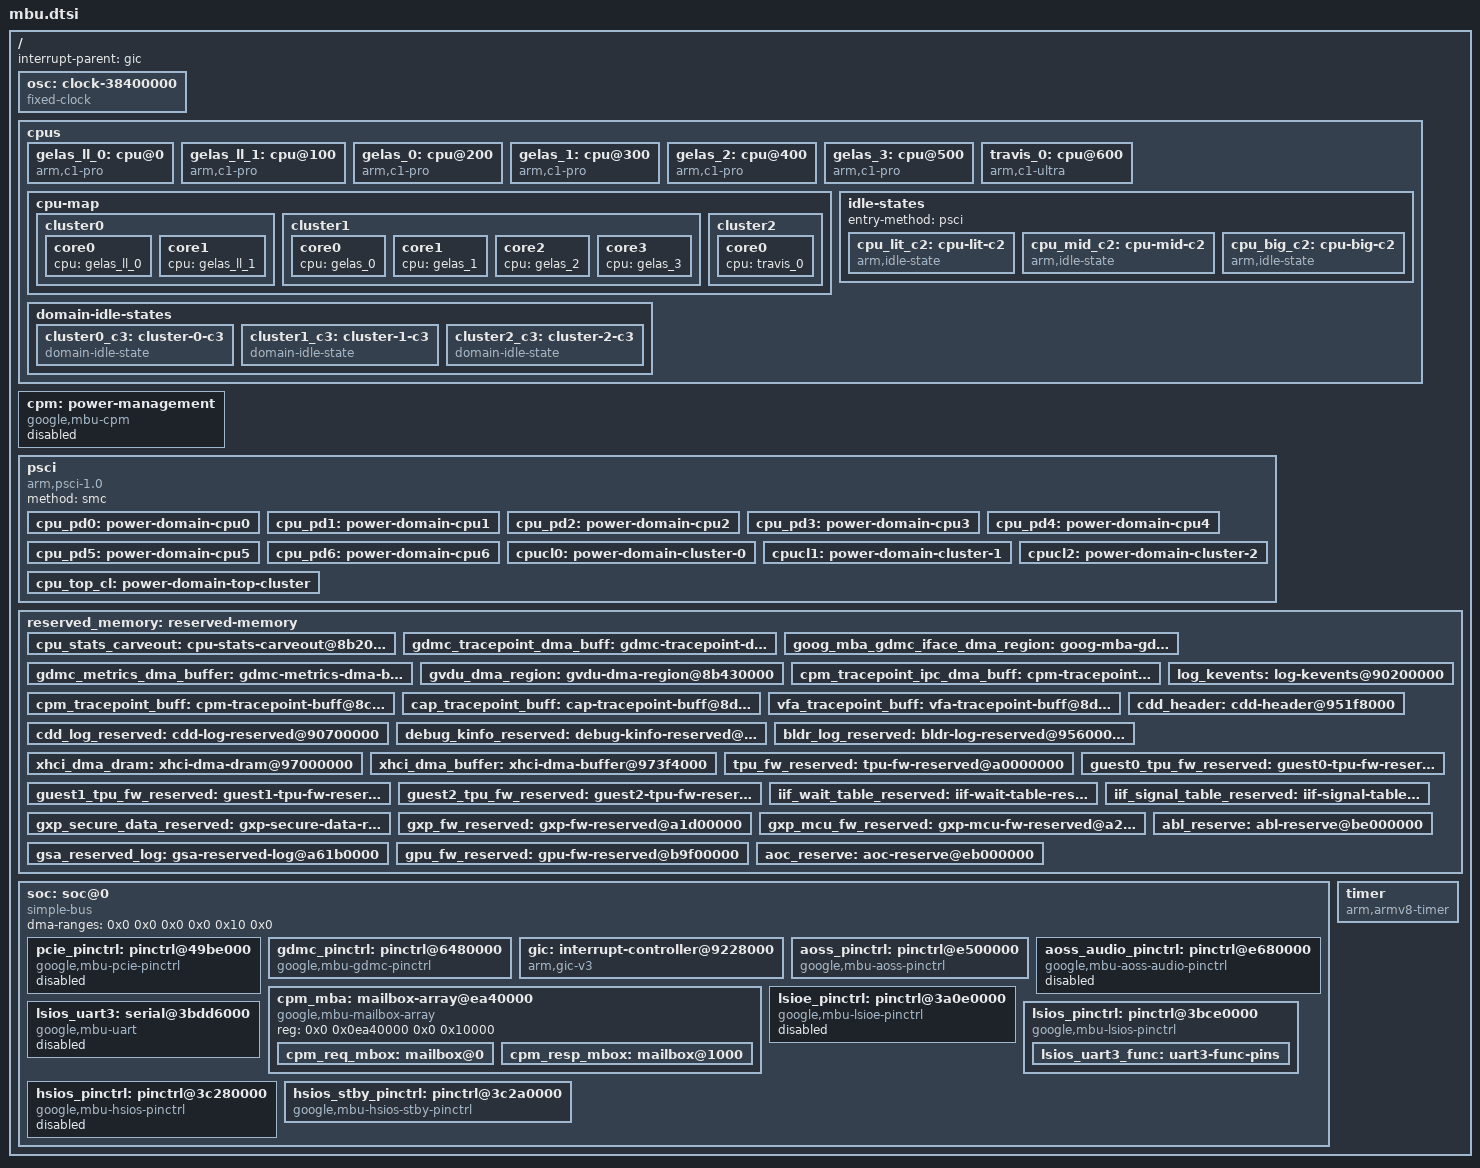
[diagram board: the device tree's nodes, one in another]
// SPDX-License-Identifier: GPL-2.0-only OR BSD-2-Clause
/*
 * Google Tensor G6 (malibu) SoC rev B0
 *
 * Copyright 2025 Google LLC.
 */

/dts-v1/;

#include <dt-bindings/clock/google,mbu-cpm.h>
#include <dt-bindings/interrupt-controller/arm-gic.h>
#include <dt-bindings/interrupt-controller/irq.h>
#include <dt-bindings/power/google,mbu-power.h>

/ {
	#address-cells = <2>;
	#size-cells = <2>;
	interrupt-parent = <&gic>;

	osc: clock-38400000 {
		compatible = "fixed-clock";
		#clock-cells = <0>;
	};

	cpus: cpus {
		#address-cells = <1>;
		#size-cells = <0>;

		gelas_ll_0: cpu@0 {
			device_type = "cpu";
			compatible = "arm,c1-pro";
			reg = <0x000>;

			#cooling-cells = <2>;
			capacity-dmips-mhz = <779>;
			enable-method = "psci";
			power-domains = <&cpu_pd0>;
			power-domain-names = "psci";
		};

		gelas_ll_1: cpu@100 {
			device_type = "cpu";
			compatible = "arm,c1-pro";
			reg = <0x100>;

			#cooling-cells = <2>;
			capacity-dmips-mhz = <779>;
			enable-method = "psci";
			power-domains = <&cpu_pd1>;
			power-domain-names = "psci";
		};

		gelas_0: cpu@200 {
			device_type = "cpu";
			compatible = "arm,c1-pro";
			reg = <0x200>;

			#cooling-cells = <2>;
			capacity-dmips-mhz = <780>;
			enable-method = "psci";
			power-domains = <&cpu_pd2>;
			power-domain-names = "psci";
		};

		gelas_1: cpu@300 {
			device_type = "cpu";
			compatible = "arm,c1-pro";
			reg = <0x300>;

			#cooling-cells = <2>;
			capacity-dmips-mhz = <780>;
			enable-method = "psci";
			power-domains = <&cpu_pd3>;
			power-domain-names = "psci";
		};

		gelas_2: cpu@400 {
			device_type = "cpu";
			compatible = "arm,c1-pro";
			reg = <0x400>;

			#cooling-cells = <2>;
			capacity-dmips-mhz = <780>;
			enable-method = "psci";
			power-domains = <&cpu_pd4>;
			power-domain-names = "psci";
		};

		gelas_3: cpu@500 {
			device_type = "cpu";
			compatible = "arm,c1-pro";
			reg = <0x500>;

			#cooling-cells = <2>;
			capacity-dmips-mhz = <780>;
			enable-method = "psci";
			power-domains = <&cpu_pd5>;
			power-domain-names = "psci";
		};

		travis_0: cpu@600 {
			device_type = "cpu";
			compatible = "arm,c1-ultra";
			reg = <0x600>;

			#cooling-cells = <2>;
			capacity-dmips-mhz = <1024>;
			enable-method = "psci";
			power-domains = <&cpu_pd6>;
			power-domain-names = "psci";
		};

		cpu-map {
			cluster0 {
				core0 {
					cpu = <&gelas_ll_0>;
				};

				core1 {
					cpu = <&gelas_ll_1>;
				};
			};

			cluster1 {
				core0 {
					cpu = <&gelas_0>;
				};

				core1 {
					cpu = <&gelas_1>;
				};

				core2 {
					cpu = <&gelas_2>;
				};

				core3 {
					cpu = <&gelas_3>;
				};
			};

			cluster2 {
				core0 {
					cpu = <&travis_0>;
				};
			};
		};

		domain-idle-states {
			cluster0_c3: cluster-0-c3 {
				compatible = "domain-idle-state";

				entry-latency-us = <800>;
				exit-latency-us = <700>;
				min-residency-us = <5000>;

				idle-state-name = "cluster0-c3";

				arm,psci-suspend-param = <0x40010033>;
			};

			cluster1_c3: cluster-1-c3 {
				compatible = "domain-idle-state";

				entry-latency-us = <1000>;
				exit-latency-us = <600>;
				min-residency-us = <5500>;

				idle-state-name = "cluster1-c3";

				arm,psci-suspend-param = <0x40010033>;
			};

			cluster2_c3: cluster-2-c3 {
				compatible = "domain-idle-state";

				entry-latency-us = <500>;
				exit-latency-us = <1000>;
				min-residency-us = <3000>;

				idle-state-name = "cluster2-c3";

				arm,psci-suspend-param = <0x40010033>;
			};
		};

		idle-states {
			entry-method = "psci";

			cpu_lit_c2: cpu-lit-c2 {
				compatible = "arm,idle-state";

				entry-latency-us = <120>;
				exit-latency-us = <300>;
				min-residency-us = <1800>;

				idle-state-name = "cpu-lit-c2";
				local-timer-stop;

				arm,psci-suspend-param = <0x40000003>;
			};

			cpu_mid_c2: cpu-mid-c2 {
				compatible = "arm,idle-state";

				entry-latency-us = <120>;
				exit-latency-us = <300>;
				min-residency-us = <1600>;

				idle-state-name = "cpu-mid-c2";
				local-timer-stop;

				arm,psci-suspend-param = <0x40000003>;
			};

			cpu_big_c2: cpu-big-c2 {
				compatible = "arm,idle-state";

				entry-latency-us = <80>;
				exit-latency-us = <400>;
				min-residency-us = <1300>;

				idle-state-name = "cpu-big-c2";
				local-timer-stop;

				arm,psci-suspend-param = <0x40000003>;
			};
		};
	};

	/*
	 * Disabled until the CPM protocol has been validated on hardware, the
	 * console must not depend on it.
	 */
	cpm: power-management {
		compatible = "google,mbu-cpm";
		mboxes = <&cpm_req_mbox>, <&cpm_resp_mbox>;
		mbox-names = "tx", "rx";
		#clock-cells = <2>;
		#power-domain-cells = <1>;

		status = "disabled";
	};

	psci {
		compatible = "arm,psci-1.0";
		method = "smc";

		cpu_pd0: power-domain-cpu0 {
			#power-domain-cells = <0>;
			domain-idle-states = <&cpu_lit_c2>;
			power-domains = <&cpucl0>;
		};

		cpu_pd1: power-domain-cpu1 {
			#power-domain-cells = <0>;
			domain-idle-states = <&cpu_lit_c2>;
			power-domains = <&cpucl0>;
		};

		cpu_pd2: power-domain-cpu2 {
			#power-domain-cells = <0>;
			domain-idle-states = <&cpu_mid_c2>;
			power-domains = <&cpucl1>;
		};

		cpu_pd3: power-domain-cpu3 {
			#power-domain-cells = <0>;
			domain-idle-states = <&cpu_mid_c2>;
			power-domains = <&cpucl1>;
		};

		cpu_pd4: power-domain-cpu4 {
			#power-domain-cells = <0>;
			domain-idle-states = <&cpu_mid_c2>;
			power-domains = <&cpucl1>;
		};

		cpu_pd5: power-domain-cpu5 {
			#power-domain-cells = <0>;
			domain-idle-states = <&cpu_mid_c2>;
			power-domains = <&cpucl1>;
		};

		cpu_pd6: power-domain-cpu6 {
			#power-domain-cells = <0>;
			domain-idle-states = <&cpu_big_c2>;
			power-domains = <&cpucl2>;
		};

		cpucl0: power-domain-cluster-0 {
			#power-domain-cells = <0>;
			domain-idle-states = <&cluster0_c3>;
			power-domains = <&cpu_top_cl>;
		};

		cpucl1: power-domain-cluster-1 {
			#power-domain-cells = <0>;
			domain-idle-states = <&cluster1_c3>;
			power-domains = <&cpu_top_cl>;
		};

		cpucl2: power-domain-cluster-2 {
			#power-domain-cells = <0>;
			domain-idle-states = <&cluster2_c3>;
			power-domains = <&cpu_top_cl>;
		};

		cpu_top_cl: power-domain-top-cluster {
			#power-domain-cells = <0>;
		};
	};

	reserved_memory: reserved-memory {
		ranges;
		#address-cells = <2>;
		#size-cells = <2>;

		cpu_stats_carveout: cpu-stats-carveout@8b20f000 {
			reg = <0x0 0x8b20f000 0x0 0x1000>;
			no-map;
		};

		gdmc_tracepoint_dma_buff: gdmc-tracepoint-dma-buff@8b400000 {
			reg = <0x0 0x8b400000 0x0 0x10000>;
			no-map;
		};

		goog_mba_gdmc_iface_dma_region: goog-mba-gdmc-iface-dma-region@8b420000 {
			reg = <0x0 0x8b420000 0x0 0x4000>;
			no-map;
		};

		gdmc_metrics_dma_buffer: gdmc-metrics-dma-buffer@8b42c000 {
			reg = <0x0 0x8b42c000 0x0 0x4000>;
			no-map;
		};

		gvdu_dma_region: gvdu-dma-region@8b430000 {
			reg = <0x0 0x8b430000 0x0 0x4000>;
			no-map;
		};

		cpm_tracepoint_ipc_dma_buff: cpm-tracepoint-ipc-dma-buff@8cdf4000 {
			reg = <0x0 0x8cdf4000 0x0 0x4000>;
			no-map;
		};

		cpm_tracepoint_buff: cpm-tracepoint-buff@8ce00000 {
			reg = <0x0 0x8ce00000 0x0 0x200000>;
			no-map;
		};

		cap_tracepoint_buff: cap-tracepoint-buff@8d000000 {
			reg = <0x0 0x8d000000 0x0 0x200000>;
			no-map;
		};

		vfa_tracepoint_buff: vfa-tracepoint-buff@8d200000 {
			reg = <0x0 0x8d200000 0x0 0x20000>;
			no-map;
		};

		log_kevents: log-kevents@90200000 {
			reg = <0x0 0x90200000 0x0 0x300000>;
			no-map;
		};

		cdd_log_reserved: cdd-log-reserved@90700000 {
			reg = <0x0 0x90700000 0x0 0x10000>;
			no-map;
		};

		debug_kinfo_reserved: debug-kinfo-reserved@90714000 {
			reg = <0x0 0x90714000 0x0 0x4000>;
			no-map;
		};

		cdd_header: cdd-header@951f8000 {
			reg = <0x0 0x951f8000 0x0 0x8000>;
			no-map;
		};

		bldr_log_reserved: bldr-log-reserved@95600000 {
			reg = <0x0 0x95600000 0x0 0x100000>;
			no-map;
		};

		xhci_dma_dram: xhci-dma-dram@97000000 {
			reg = <0x0 0x97000000 0x0 0x3f4000>;
			no-map;
		};

		xhci_dma_buffer: xhci-dma-buffer@973f4000 {
			reg = <0x0 0x973f4000 0x0 0xc000>;
			no-map;
		};

		tpu_fw_reserved: tpu-fw-reserved@a0000000 {
			reg = <0x0 0xa0000000 0x0 0xa00000>;
			no-map;
		};

		guest0_tpu_fw_reserved: guest0-tpu-fw-reserved@a0a00000 {
			reg = <0x0 0xa0a00000 0x0 0x200000>;
			no-map;
		};

		guest1_tpu_fw_reserved: guest1-tpu-fw-reserved@a0c00000 {
			reg = <0x0 0xa0c00000 0x0 0x200000>;
			no-map;
		};

		guest2_tpu_fw_reserved: guest2-tpu-fw-reserved@a0e00000 {
			reg = <0x0 0xa0e00000 0x0 0x200000>;
			no-map;
		};

		iif_wait_table_reserved: iif-wait-table-reserved@a1360000 {
			reg = <0x0 0xa1360000 0x0 0x20000>;
			no-map;
		};

		iif_signal_table_reserved: iif-signal-table-reserved@a1380000 {
			reg = <0x0 0xa1380000 0x0 0x20000>;
			no-map;
		};

		gxp_secure_data_reserved: gxp-secure-data-reserved@a1400000 {
			reg = <0x0 0xa1400000 0x0 0x900000>;
			no-map;
		};

		gxp_fw_reserved: gxp-fw-reserved@a1d00000 {
			reg = <0x0 0xa1d00000 0x0 0x300000>;
			no-map;
		};

		gxp_mcu_fw_reserved: gxp-mcu-fw-reserved@a2000000 {
			reg = <0x0 0xa2000000 0x0 0x400000>;
			no-map;
		};

		gsa_reserved_log: gsa-reserved-log@a61b0000 {
			reg = <0x0 0xa61b0000 0x0 0x4000>;
			no-map;
		};

		gpu_fw_reserved: gpu-fw-reserved@b9f00000 {
			reg = <0x0 0xb9f00000 0x0 0x2100000>;
			no-map;
		};

		abl_reserve: abl-reserve@be000000 {
			reg = <0x0 0xbe000000 0x0 0x1000000>;
			no-map;
		};

		aoc_reserve: aoc-reserve@eb000000 {
			reg = <0x0 0xeb000000 0x0 0x4000000>;
			no-map;
		};
	};

	soc: soc@0 {
		compatible = "simple-bus";
		ranges = <0x0 0x0 0x0 0x0 0x10 0x0>;

		dma-ranges = <0x0 0x0 0x0 0x0 0x10 0x0>;

		#address-cells = <2>;
		#size-cells = <2>;

		pcie_pinctrl: pinctrl@49be000 {
			compatible = "google,mbu-pcie-pinctrl";
			reg = <0x0 0x049be000 0x0 0x5000>;
			gpio-controller;
			#gpio-cells = <2>;
			gpio-ranges = <&pcie_pinctrl 0 0 5>;
			gpio-reserved-ranges = <4 1>;

			power-domains = <&cpm MBU_PD_PCIE>;

			/* Needs the CPM, which is disabled for now. */
			status = "disabled";
		};

		gdmc_pinctrl: pinctrl@6480000 {
			compatible = "google,mbu-gdmc-pinctrl";
			reg = <0x0 0x06480000 0x0 0x15000>;
			gpio-controller;
			#gpio-cells = <2>;
			gpio-ranges = <&gdmc_pinctrl 0 0 21>;
			gpio-reserved-ranges = <7 8>;
		};

		gic: interrupt-controller@9228000 {
			compatible = "arm,gic-v3";
			reg = <0x0 0x09228000 0x0 0x10000>,
			      <0x0 0x092a8000 0x0 0x200000>;

			#address-cells = <0>;

			#interrupt-cells = <4>;
			interrupt-controller;
			interrupts = <GIC_PPI 9 IRQ_TYPE_LEVEL_HIGH 0>;
		};

		aoss_pinctrl: pinctrl@e500000 {
			compatible = "google,mbu-aoss-pinctrl";
			reg = <0x0 0x0e500000 0x0 0x7b000>;
			gpio-controller;
			#gpio-cells = <2>;
			gpio-ranges = <&aoss_pinctrl 0 0 123>;
			gpio-reserved-ranges = <66 4>;
		};

		aoss_audio_pinctrl: pinctrl@e680000 {
			compatible = "google,mbu-aoss-audio-pinctrl";
			reg = <0x0 0x0e680000 0x0 0x20000>;
			gpio-controller;
			#gpio-cells = <2>;
			gpio-ranges = <&aoss_audio_pinctrl 0 0 30>;
			gpio-reserved-ranges = <1 1>, <3 1>, <5 1>, <7 1>, <10 1>,
					       <14 1>, <18 1>, <27 1>;

			/* Shared with the audio DSP, which may power it down. */
			status = "disabled";
		};

		cpm_mba: mailbox-array@ea40000 {
			compatible = "google,mbu-mailbox-array", "google,mailbox-array";
			reg = <0x0 0x0ea40000 0x0 0x10000>;
			ranges = <0x0 0x0 0x0ea60000 0x2000>;

			#address-cells = <1>;
			#size-cells = <1>;

			cpm_req_mbox: mailbox@0 {
				reg = <0x0000 0x1000>;
				interrupts = <GIC_SPI 15 IRQ_TYPE_LEVEL_HIGH 0>;
				#mbox-cells = <0>;
				google,mba-queue-mode;
			};

			cpm_resp_mbox: mailbox@1000 {
				reg = <0x1000 0x1000>;
				interrupts = <GIC_SPI 16 IRQ_TYPE_LEVEL_HIGH 0>;
				#mbox-cells = <0>;
				google,rx-payload-words = <4>;
				google,mba-queue-mode;
			};
		};

		lsioe_pinctrl: pinctrl@3a0e0000 {
			compatible = "google,mbu-lsioe-pinctrl";
			reg = <0x0 0x3a0e0000 0x0 0x25000>;
			gpio-controller;
			#gpio-cells = <2>;
			gpio-ranges = <&lsioe_pinctrl 0 0 37>;

			power-domains = <&cpm MBU_PD_LSIO_E_CLI_GPIO>;

			/* Needs the CPM, which is disabled for now. */
			status = "disabled";
		};

		lsios_pinctrl: pinctrl@3bce0000 {
			compatible = "google,mbu-lsios-pinctrl";
			reg = <0x0 0x3bce0000 0x0 0x44000>;
			gpio-controller;
			#gpio-cells = <2>;
			gpio-ranges = <&lsios_pinctrl 0 0 68>;
			gpio-reserved-ranges = <51 1>;

			lsios_uart3_func: uart3-func-pins {
				pins = "XLSIOS_SPIU3_MISO_RXD",
				       "XLSIOS_SPIU3_MOSI_TXD";
				function = "lsios_uart3";
				output-disable;
				input-enable;
			};
		};

		lsios_uart3: serial@3bdd6000 {
			compatible = "google,mbu-uart", "snps,dw-apb-uart";
			reg = <0x0 0x3bdd6000 0x0 0x100>;

			clock-frequency = <200000000>;
			interrupts = <GIC_SPI 400 IRQ_TYPE_LEVEL_HIGH 0>;
			reg-io-width = <4>;
			reg-shift = <2>;
			pinctrl-0 = <&lsios_uart3_func>;
			pinctrl-names = "default";

			status = "disabled";
		};

		hsios_pinctrl: pinctrl@3c280000 {
			compatible = "google,mbu-hsios-pinctrl";
			reg = <0x0 0x3c280000 0x0 0xd000>;
			gpio-controller;
			#gpio-cells = <2>;
			gpio-ranges = <&hsios_pinctrl 0 0 13>;
			gpio-reserved-ranges = <12 1>;

			power-domains = <&cpm MBU_PD_HSIO_S>;

			/* Needs the CPM, which is disabled for now. */
			status = "disabled";
		};

		hsios_stby_pinctrl: pinctrl@3c2a0000 {
			compatible = "google,mbu-hsios-stby-pinctrl";
			reg = <0x0 0x3c2a0000 0x0 0x2000>;
			gpio-controller;
			#gpio-cells = <2>;
			gpio-ranges = <&hsios_stby_pinctrl 0 0 2>;
			gpio-reserved-ranges = <1 1>;
		};
	};

	timer {
		compatible = "arm,armv8-timer";
		interrupts = <GIC_PPI 13 IRQ_TYPE_LEVEL_LOW 0>,
			     <GIC_PPI 14 IRQ_TYPE_LEVEL_LOW 0>,
			     <GIC_PPI 11 IRQ_TYPE_LEVEL_LOW 0>,
			     <GIC_PPI 10 IRQ_TYPE_LEVEL_LOW 0>;
	};
};
